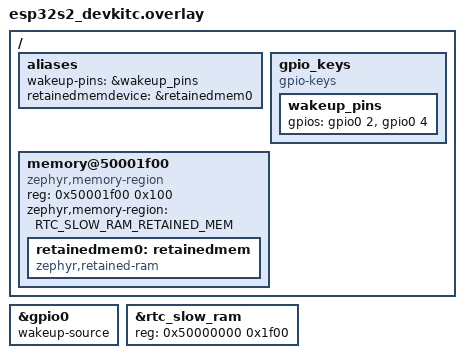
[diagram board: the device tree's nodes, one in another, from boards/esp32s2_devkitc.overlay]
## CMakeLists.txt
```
# SPDX-License-Identifier: Apache-2.0

cmake_minimum_required(VERSION 3.28.0)
find_package(Zephyr REQUIRED HINTS $ENV{ZEPHYR_BASE})
project(esp32_deep_sleep)

target_sources(app PRIVATE src/main.c)
```

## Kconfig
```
# Copyright (c) 2022-2026 Espressif Systems (Shanghai) Co., Ltd.
# SPDX-License-Identifier: Apache-2.0

mainmenu "Espressif Deep Sleep demo"

config EXAMPLE_WAKEUP_TIME_SEC
	int "Wakeup time in seconds"
	default 5
	help
	  This option sets the time in seconds after which the device
	  will wake up from deep sleep. The value must be greater than 0.

source "Kconfig.zephyr"
```

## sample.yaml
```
sample:
  description: Sample application to test ESP32 deep-sleep mode
  name: ESP32 Deep-sleep
tests:
  sample.esp32.deep_sleep.build_only:
    build_only: true
    platform_allow:
      - esp32_devkitc/esp32/procpu
      - esp32c3_devkitc
      - esp32c5_devkitc/esp32c5/hpcore
      - esp32c6_devkitc/esp32c6/hpcore
      - esp32s2_devkitc
      - esp32s3_devkitc/esp32s3/procpu
      - esp32h2_devkitm
      - esp8684_devkitm
  sample.esp32.deep_sleep.dut:
    extra_args:
      - CONFIG_EXAMPLE_WAKEUP_TIME_SEC=1
      - CONFIG_ESP32_USE_UNSUPPORTED_REVISION=y
    platform_allow:
      - esp32_devkitc/esp32/procpu
      - esp32c3_devkitc
      - esp32c5_devkitc/esp32c5/hpcore
      - esp32c6_devkitc/esp32c6/hpcore
      - esp32s2_devkitc
      - esp32s3_devkitc/esp32s3/procpu
      - esp32h2_devkitm
      - esp8684_devkitm
    tags: esp32
    harness: console
    harness_config:
      type: multi_line
      regex:
        - "Powering off"
        - "Wake up from timer"
```

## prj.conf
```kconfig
CONFIG_PM=y
CONFIG_PM_DEVICE=y
CONFIG_POWEROFF=y
CONFIG_RETAINED_MEM=y
```

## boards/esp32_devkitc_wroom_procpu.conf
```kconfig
# Enables GPIO2 and GPIO4 as wakeup sources
CONFIG_EXAMPLE_EXT1_WAKEUP=y
```

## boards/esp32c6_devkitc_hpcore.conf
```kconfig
CONFIG_RETAINED_MEM=y
```

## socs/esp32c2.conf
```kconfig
CONFIG_RETAINED_MEM=n
```

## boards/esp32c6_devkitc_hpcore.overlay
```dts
/*
 * Copyright (c) 2026 Espressif Systems (Shanghai) Co., Ltd.
 *
 * SPDX-License-Identifier: Apache-2.0
 */

/ {
	aliases {
		wakeup-gpios = &wakeup_pins;
	};

	gpio_keys {
		compatible = "gpio-keys";

		wakeup_pins: wakeup_pins {
			gpios = <&gpio0 2 (GPIO_PULL_DOWN | GPIO_ACTIVE_HIGH | GPIO_INT_WAKEUP)>,
				<&gpio0 4 (GPIO_PULL_DOWN | GPIO_ACTIVE_HIGH | GPIO_INT_WAKEUP)>;
		};
	};
};

&gpio0 {
	/* Configure device as wakeup source */
	wakeup-source;
};
```

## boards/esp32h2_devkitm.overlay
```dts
/*
 * Copyright (c) 2025-2026 Espressif Systems (Shanghai) Co., Ltd.
 *
 * SPDX-License-Identifier: Apache-2.0
 */

/ {
	aliases {
		wakeup-pins = &wakeup_pins;
		retainedmemdevice = &retainedmem0;
	};

	gpio_keys {
		compatible = "gpio-keys";

		wakeup_pins: wakeup_pins {
			gpios = <&gpio0 10 (GPIO_PULL_DOWN | GPIO_ACTIVE_HIGH | GPIO_INT_WAKEUP)>,
				<&gpio0 11 (GPIO_PULL_DOWN | GPIO_ACTIVE_HIGH | GPIO_INT_WAKEUP)>;
		};
	};

	memory@50000f00 {
		compatible = "zephyr,memory-region", "mmio-sram";
		reg = <0x50000f00 0x100>;
		zephyr,memory-region = "SRAMLP_RETAINED_MEM";
		status = "okay";

		retainedmem0: retainedmem {
			compatible = "zephyr,retained-ram";
			status = "okay";
		};
	};
};

&sramlp {
	/* Shrink sramlp size to avoid overlap with retained memory region:
	 * 4KB - 256 = 0xf00
	 */
	reg = <0x50000000 0xf00>;
};
```

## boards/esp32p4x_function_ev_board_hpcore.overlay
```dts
/*
 * Copyright (c) 2026 Espressif Systems (Shanghai) Co., Ltd.
 *
 * SPDX-License-Identifier: Apache-2.0
 */

/ {
	aliases {
		wakeup-pins = &wakeup_pins;
	};

	gpio_keys {
		compatible = "gpio-keys";

		wakeup_pins: wakeup_pins {
			gpios = <&gpio0 2 (GPIO_PULL_DOWN | GPIO_ACTIVE_HIGH | GPIO_INT_WAKEUP)>;
		};
	};
};
```

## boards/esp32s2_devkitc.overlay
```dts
/*
 * Copyright (c) 2025-2026 Espressif Systems (Shanghai) Co., Ltd.
 *
 * SPDX-License-Identifier: Apache-2.0
 */

/ {
	aliases {
		wakeup-pins = &wakeup_pins;
		retainedmemdevice = &retainedmem0;
	};

	gpio_keys {
		compatible = "gpio-keys";

		wakeup_pins: wakeup_pins {
			gpios = <&gpio0 2 (GPIO_PULL_DOWN | GPIO_ACTIVE_HIGH | GPIO_INT_WAKEUP)>,
				<&gpio0 4 (GPIO_PULL_DOWN | GPIO_ACTIVE_HIGH | GPIO_INT_WAKEUP)>;
		};
	};

	memory@50001f00 {
		compatible = "zephyr,memory-region", "mmio-sram";
		reg = <0x50001f00 0x100>;
		zephyr,memory-region = "RTC_SLOW_RAM_RETAINED_MEM";
		status = "okay";

		retainedmem0: retainedmem {
			compatible = "zephyr,retained-ram";
			status = "okay";
		};
	};
};

&gpio0 {
	/* Configure device as wakeup source */
	wakeup-source;
};

&rtc_slow_ram {
	/* Shrink rtc_slow_ram size to avoid overlap with retained memory region:
	 * 8KB - 256 = 0x1f00
	 */
	reg = <0x50000000 0x1f00>;
};
```

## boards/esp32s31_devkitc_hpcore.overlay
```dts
/*
 * Copyright (c) 2026 Espressif Systems (Shanghai) Co., Ltd.
 *
 * SPDX-License-Identifier: Apache-2.0
 */

/ {
	aliases {
		wakeup-pins = &wakeup_pins;
	};

	gpio_keys {
		compatible = "gpio-keys";

		wakeup_pins: wakeup_pins {
			gpios = <&gpio0 2 (GPIO_PULL_DOWN | GPIO_ACTIVE_HIGH | GPIO_INT_WAKEUP)>,
				<&gpio0 4 (GPIO_PULL_DOWN | GPIO_ACTIVE_HIGH | GPIO_INT_WAKEUP)>;
		};
	};
};
```

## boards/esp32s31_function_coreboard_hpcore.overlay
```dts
/*
 * Copyright (c) 2026 Espressif Systems (Shanghai) Co., Ltd.
 *
 * SPDX-License-Identifier: Apache-2.0
 */

/ {
	aliases {
		wakeup-pins = &wakeup_pins;
	};

	gpio_keys {
		compatible = "gpio-keys";

		wakeup_pins: wakeup_pins {
			gpios = <&gpio0 2 (GPIO_PULL_DOWN | GPIO_ACTIVE_HIGH | GPIO_INT_WAKEUP)>,
				<&gpio0 3 (GPIO_PULL_DOWN | GPIO_ACTIVE_HIGH | GPIO_INT_WAKEUP)>;
		};
	};
};
```

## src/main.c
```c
/*
 * Copyright (c) 2022-2026 Espressif Systems (Shanghai) Co., Ltd.
 *
 * SPDX-License-Identifier: Apache-2.0
 */
#include <zephyr/kernel.h>
#include <zephyr/drivers/gpio.h>
#include <zephyr/drivers/retained_mem.h>
#include <zephyr/sys/poweroff.h>
#include <esp_sleep.h>

#include <esp_attr.h>

#define RETAINED_MEM_CONST 0x01234567

#define WAKE_GPIOS DT_ALIAS(wakeup_pins)

#if !DT_NODE_HAS_STATUS_OKAY(WAKE_GPIOS)
#error "Unsupported: wakeup-pins node/alias not defined"
#endif

#define BUILD_GPIO_SPEC(node_id, prop, idx) GPIO_DT_SPEC_GET_BY_IDX(node_id, prop, idx),

static const struct gpio_dt_spec wake_gpios[] = {
	DT_FOREACH_PROP_ELEM(WAKE_GPIOS, gpios, BUILD_GPIO_SPEC)};

static esp_sleep_wakeup_cause_t get_wakeup_cause(void)
{
	uint32_t causes = esp_sleep_get_wakeup_causes();

	if (causes == 0) {
		return ESP_SLEEP_WAKEUP_UNDEFINED;
	}
	return (esp_sleep_wakeup_cause_t)__builtin_ctz(causes);
}

static void print_counter(__maybe_unused esp_sleep_wakeup_cause_t sleep_wakeup_cause)
{
#ifdef CONFIG_RETAINED_MEM
	const struct device *retained_mem_device = DEVICE_DT_GET(DT_ALIAS(retainedmemdevice));

	off_t offset;
	uint32_t aux;
	int err;

	if (!device_is_ready(retained_mem_device)) {
		printk("retained_mem device is not ready!\n");
		return;
	}

	switch (sleep_wakeup_cause) {
	case ESP_SLEEP_WAKEUP_EXT1:
	case ESP_SLEEP_WAKEUP_GPIO:
	case ESP_SLEEP_WAKEUP_TIMER:
		offset = 0;
		err = retained_mem_read(retained_mem_device, offset, (uint8_t *)&aux, sizeof(aux));
		if (err < 0) {
			printk("retained_mem_read() failed: %d\n", err);
			return;
		}

		if (aux != RETAINED_MEM_CONST) {
			printk("retained_mem_read() retrieved wrong value - expected: "
				STRINGIFY(RETAINED_MEM_CONST) "; actual: 0x%" PRIx32 "\n", aux);
			return;
		}

		offset += sizeof(aux);
		err = retained_mem_read(retained_mem_device, offset, (uint8_t *)&aux, sizeof(aux));
		if (err < 0) {
			printk("retained_mem_read() failed: %d\n", err);
			return;
		}

		printk("ESP32 deep sleep example, current counter is %" PRIu32 "\n", aux++);

		err = retained_mem_write(retained_mem_device, offset, (uint8_t *)&aux, sizeof(aux));
		if (err < 0) {
			printk("retained_mem_write() failed: %d\n", err);
			return;
		}
		break;
	case ESP_SLEEP_WAKEUP_UNDEFINED:
	default:
		aux = RETAINED_MEM_CONST;
		offset = 0;
		err = retained_mem_write(retained_mem_device, offset, (uint8_t *)&aux, sizeof(aux));
		if (err < 0) {
			printk("retained_mem_write() failed: %d\n", err);
			return;
		}

		aux = 1;
		offset += sizeof(aux);
		err = retained_mem_write(retained_mem_device, offset, (uint8_t *)&aux, sizeof(aux));
		if (err < 0) {
			printk("retained_mem_write() failed: %d\n", err);
			return;
		}
	}
#endif /* CONFIG_RETAINED_MEM */
}

int main(void)
{
	esp_sleep_wakeup_cause_t sleep_wakeup_cause = get_wakeup_cause();

	print_counter(sleep_wakeup_cause);

	switch (sleep_wakeup_cause) {
	case ESP_SLEEP_WAKEUP_EXT1:
	case ESP_SLEEP_WAKEUP_GPIO: {
		uint64_t wakeup_pin_mask = 0;
#ifdef SOC_PM_SUPPORT_EXT1_WAKEUP
		wakeup_pin_mask = esp_sleep_get_ext1_wakeup_status();
#elif defined(SOC_GPIO_SUPPORT_DEEPSLEEP_WAKEUP)
		wakeup_pin_mask = esp_sleep_get_gpio_wakeup_status();
#endif
		if (wakeup_pin_mask != 0) {
			int pin = __builtin_ffsll(wakeup_pin_mask) - 1;

			printk("Wake up from GPIO %d\n", pin);
		} else {
			printk("Wake up from GPIO\n");
		}
		break;
	}
	case ESP_SLEEP_WAKEUP_TIMER:
		printk("Wake up from timer.\n");
		break;
	case ESP_SLEEP_WAKEUP_UNDEFINED:
	default:
		printk("Not a deep sleep reset\n");
	}

	k_busy_wait(1000000);

	for (int i = 0; i < ARRAY_SIZE(wake_gpios); i++) {
		const struct gpio_dt_spec *g = &wake_gpios[i];

		int ret = gpio_pin_configure_dt(g, g->dt_flags | GPIO_INPUT);

		if (ret != 0) {
			printk("Error %d: failed to configure %s pin %d\n", ret, g->port->name,
			       g->pin);
			return 0;
		}
	}

	const int wakeup_time_sec = CONFIG_EXAMPLE_WAKEUP_TIME_SEC;

	printk("Enabling timer wakeup, %ds\n", wakeup_time_sec);

	/* Since sys_poweroff() is being called directly, timer wakeup
	 * must be programmed by application.
	 */
	esp_sleep_enable_timer_wakeup(wakeup_time_sec * 1000000);

	printk("Powering off\n");
	sys_poweroff();

	return 0;
}
```
